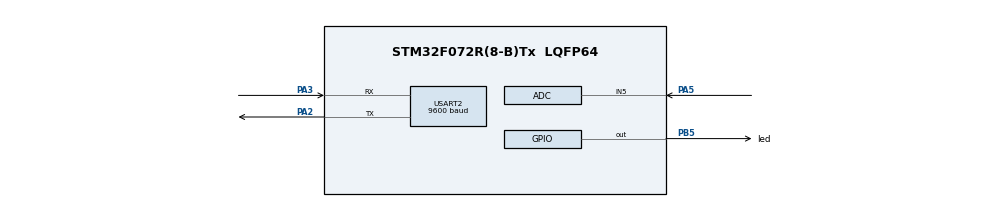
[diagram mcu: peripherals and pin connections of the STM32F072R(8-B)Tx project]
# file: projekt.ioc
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ADC.ClockPrescaler=ADC_CLOCK_ASYNC_DIV1
ADC.ContinuousConvMode=DISABLE
ADC.Overrun=ADC_OVR_DATA_PRESERVED
Mcu.Family=STM32F0
Mcu.Name=STM32F072R(8-B)Tx
Mcu.Package=LQFP64
PA2.Mode=Asynchronous
PA2.Signal=USART2_TX
PA3.Mode=Asynchronous
PA3.Signal=USART2_RX
PA5.Mode=IN5
PA5.Signal=ADC_IN5
PB5.GPIO_Label=led
PB5.Signal=GPIO_Output
ProjectManager.HeapSize=0x200
ProjectManager.StackSize=0x400
ProjectManager.TargetToolchain=STM32CubeIDE
USART2.BaudRate=9600
USART2.VirtualMode-Asynchronous=VM_ASYNC
board=custom

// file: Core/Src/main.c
/* USER CODE BEGIN Header */
/**
  ******************************************************************************
  * @file           : main.c
  * @brief          : Main program body
  ******************************************************************************
  * @attention
  *
  * Copyright (c) 2022 STMicroelectronics.
  * All rights reserved.
  *
  * This software is licensed under terms that can be found in the LICENSE file
  * in the root directory of this software component.
  * If no LICENSE file comes with this software, it is provided AS-IS.
  *
  ******************************************************************************
  */
/* USER CODE END Header */
#include "main.h"

 ADC_HandleTypeDef hadc;

UART_HandleTypeDef huart2;

/* USER CODE BEGIN PV */
uint16_t adc_val;
/* USER CODE END PV */

void SystemClock_Config(void);
static void MX_GPIO_Init(void);
static void MX_USART2_UART_Init(void);
static void MX_ADC_Init(void);

int main(void)
{

  /* MCU Configuration--------------------------------------------------------*/

  /* Reset of all peripherals, Initializes the Flash interface and the Systick. */
  HAL_Init();

  /* Configure the system clock */
  SystemClock_Config();

  /* Initialize all configured peripherals */
  MX_GPIO_Init();
  MX_USART2_UART_Init();
  MX_ADC_Init();
  /* USER CODE BEGIN 2 */
  HAL_ADC_Start(&hadc);
  /* USER CODE END 2 */

  /* Infinite loop */
  /* USER CODE BEGIN WHILE */
  int liczba = 28;
  char buffer[20];

  while (1)
  {

	  if(HAL_ADC_PollForConversion(&hadc, 5)==HAL_OK)
	  {
		  adc_val = HAL_ADC_GetValue(&hadc);
		  liczba = (int)adc_val;
		  itoa(liczba, buffer, 10);
		  if(liczba > 157) {
			  HAL_GPIO_WritePin(led_GPIO_Port, led_Pin, 1);
		  } else HAL_GPIO_WritePin(led_GPIO_Port, led_Pin, 0);
		  HAL_UART_Transmit(&huart2, buffer, (sizeof(buffer)/8) + 1, 1000);
		  HAL_UART_Transmit(&huart2, " ", 2, 1000);
		  HAL_ADC_Start(&hadc);
	  }

    /* USER CODE END WHILE */

  }
}

void SystemClock_Config(void)
{
  RCC_OscInitTypeDef RCC_OscInitStruct = {0};
  RCC_ClkInitTypeDef RCC_ClkInitStruct = {0};
  RCC_PeriphCLKInitTypeDef PeriphClkInit = {0};

  /** Initializes the RCC Oscillators according to the specified parameters
  * in the RCC_OscInitTypeDef structure.
  */
  RCC_OscInitStruct.OscillatorType = RCC_OSCILLATORTYPE_HSI|RCC_OSCILLATORTYPE_HSI14;
  RCC_OscInitStruct.HSIState = RCC_HSI_ON;
  RCC_OscInitStruct.HSI14State = RCC_HSI14_ON;
  RCC_OscInitStruct.HSICalibrationValue = RCC_HSICALIBRATION_DEFAULT;
  RCC_OscInitStruct.HSI14CalibrationValue = 16;
  RCC_OscInitStruct.PLL.PLLState = RCC_PLL_NONE;
  if (HAL_RCC_OscConfig(&RCC_OscInitStruct) != HAL_OK)
  {
    Error_Handler();
  }

  /** Initializes the CPU, AHB and APB buses clocks
  */
  RCC_ClkInitStruct.ClockType = RCC_CLOCKTYPE_HCLK|RCC_CLOCKTYPE_SYSCLK
                              |RCC_CLOCKTYPE_PCLK1;
  RCC_ClkInitStruct.SYSCLKSource = RCC_SYSCLKSOURCE_HSI;
  RCC_ClkInitStruct.AHBCLKDivider = RCC_SYSCLK_DIV1;
  RCC_ClkInitStruct.APB1CLKDivider = RCC_HCLK_DIV1;

  if (HAL_RCC_ClockConfig(&RCC_ClkInitStruct, FLASH_LATENCY_0) != HAL_OK)
  {
    Error_Handler();
  }
  PeriphClkInit.PeriphClockSelection = RCC_PERIPHCLK_USART2;
  PeriphClkInit.Usart2ClockSelection = RCC_USART2CLKSOURCE_PCLK1;
  if (HAL_RCCEx_PeriphCLKConfig(&PeriphClkInit) != HAL_OK)
  {
    Error_Handler();
  }
}

static void MX_ADC_Init(void)
{

  ADC_ChannelConfTypeDef sConfig = {0};

  /** Configure the global features of the ADC (Clock, Resolution, Data Alignment and number of conversion)
  */
  hadc.Instance = ADC1;
  hadc.Init.ClockPrescaler = ADC_CLOCK_ASYNC_DIV1;
  hadc.Init.Resolution = ADC_RESOLUTION_12B;
  hadc.Init.DataAlign = ADC_DATAALIGN_RIGHT;
  hadc.Init.ScanConvMode = ADC_SCAN_DIRECTION_FORWARD;
  hadc.Init.EOCSelection = ADC_EOC_SINGLE_CONV;
  hadc.Init.LowPowerAutoWait = DISABLE;
  hadc.Init.LowPowerAutoPowerOff = DISABLE;
  hadc.Init.ContinuousConvMode = DISABLE;
  hadc.Init.DiscontinuousConvMode = DISABLE;
  hadc.Init.ExternalTrigConv = ADC_SOFTWARE_START;
  hadc.Init.ExternalTrigConvEdge = ADC_EXTERNALTRIGCONVEDGE_NONE;
  hadc.Init.DMAContinuousRequests = DISABLE;
  hadc.Init.Overrun = ADC_OVR_DATA_PRESERVED;
  if (HAL_ADC_Init(&hadc) != HAL_OK)
  {
    Error_Handler();
  }

  /** Configure for the selected ADC regular channel to be converted.
  */
  sConfig.Channel = ADC_CHANNEL_5;
  sConfig.Rank = ADC_RANK_CHANNEL_NUMBER;
  sConfig.SamplingTime = ADC_SAMPLETIME_1CYCLE_5;
  if (HAL_ADC_ConfigChannel(&hadc, &sConfig) != HAL_OK)
  {
    Error_Handler();
  }

}

static void MX_USART2_UART_Init(void)
{

  huart2.Instance = USART2;
  huart2.Init.BaudRate = 9600;
  huart2.Init.WordLength = UART_WORDLENGTH_8B;
  huart2.Init.StopBits = UART_STOPBITS_1;
  huart2.Init.Parity = UART_PARITY_NONE;
  huart2.Init.Mode = UART_MODE_TX_RX;
  huart2.Init.HwFlowCtl = UART_HWCONTROL_NONE;
  huart2.Init.OverSampling = UART_OVERSAMPLING_16;
  huart2.Init.OneBitSampling = UART_ONE_BIT_SAMPLE_DISABLE;
  huart2.AdvancedInit.AdvFeatureInit = UART_ADVFEATURE_NO_INIT;
  if (HAL_UART_Init(&huart2) != HAL_OK)
  {
    Error_Handler();
  }

}

static void MX_GPIO_Init(void)
{
  GPIO_InitTypeDef GPIO_InitStruct = {0};

  /* GPIO Ports Clock Enable */
  __HAL_RCC_GPIOA_CLK_ENABLE();
  __HAL_RCC_GPIOB_CLK_ENABLE();

  /*Configure GPIO pin Output Level */
  HAL_GPIO_WritePin(led_GPIO_Port, led_Pin, GPIO_PIN_RESET);

  /*Configure GPIO pin : led_Pin */
  GPIO_InitStruct.Pin = led_Pin;
  GPIO_InitStruct.Mode = GPIO_MODE_OUTPUT_PP;
  GPIO_InitStruct.Pull = GPIO_NOPULL;
  GPIO_InitStruct.Speed = GPIO_SPEED_FREQ_LOW;
  HAL_GPIO_Init(led_GPIO_Port, &GPIO_InitStruct);

}

void Error_Handler(void)
{
  __disable_irq();
  while (1)
  {
  }
}
